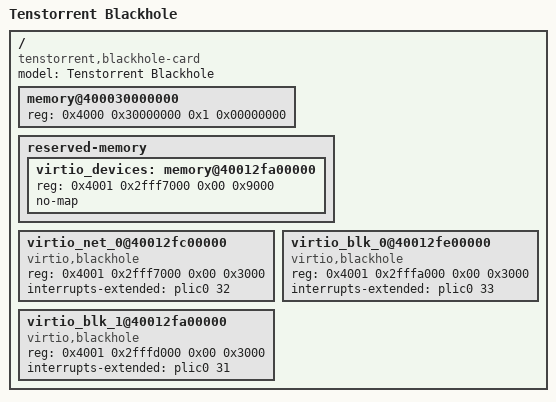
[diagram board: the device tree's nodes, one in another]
// SPDX-License-Identifier: (GPL-2.0 OR MIT)
/dts-v1/;

#include "blackhole.dtsi"

/ {
	model = "Tenstorrent Blackhole";
	compatible = "tenstorrent,blackhole-card", "tenstorrent,blackhole";

	memory@400030000000 {
		device_type = "memory";
		reg = <0x4000 0x30000000 0x1 0x00000000>;
	};

	reserved-memory {
		#address-cells = <2>;
		#size-cells = <2>;
		ranges;

		virtio_devices: memory@40012fa00000 {
			reg = <0x4001 0x2fff7000 0x00 0x9000>;
			no-map;
		};
	};

	virtio_net_0@40012fc00000 {
		compatible = "virtio,blackhole";
		reg = <0x4001 0x2fff7000 0x00 0x3000>;
		interrupts-extended = <&plic0 32>;
	};

	virtio_blk_0@40012fe00000 {
		compatible = "virtio,blackhole";
		reg = <0x4001 0x2fffa000 0x00 0x3000>;
		interrupts-extended = <&plic0 33>;
	};

	virtio_blk_1@40012fa00000 {
		compatible = "virtio,blackhole";
		reg = <0x4001 0x2fffd000 0x00 0x3000>;
		interrupts-extended = <&plic0 31>;
	};
};
